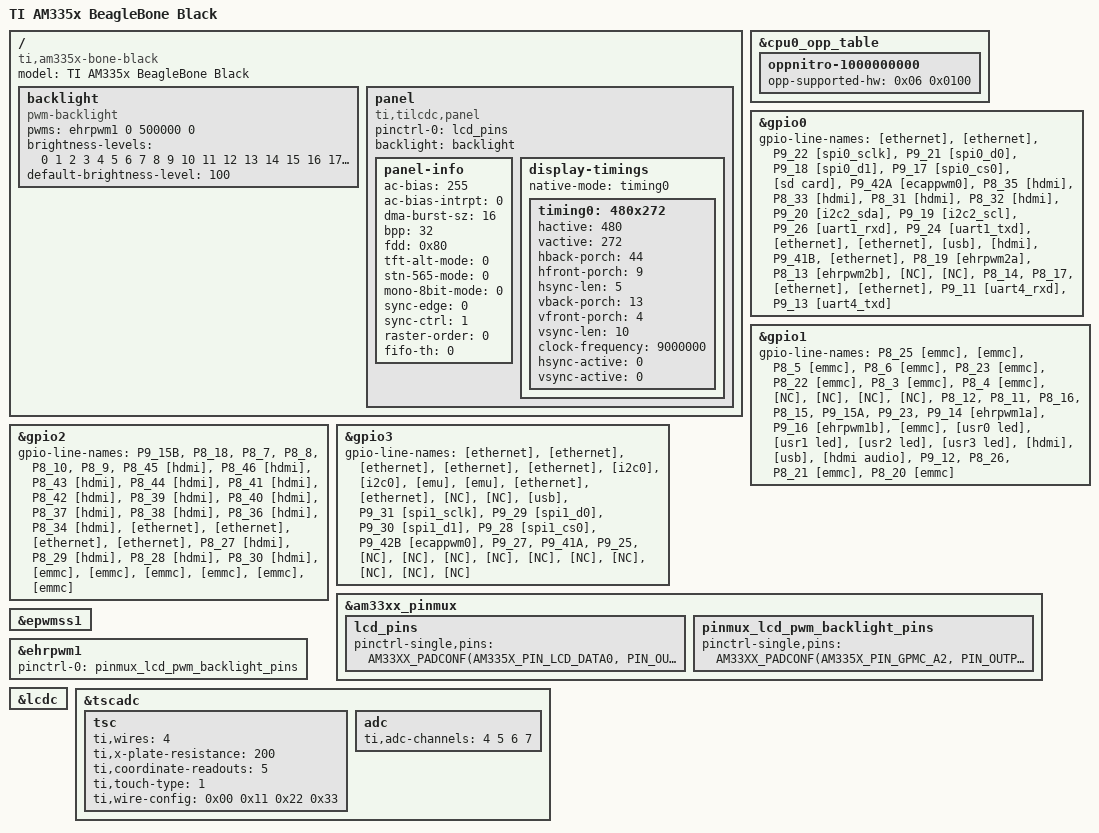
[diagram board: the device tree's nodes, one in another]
// SPDX-License-Identifier: GPL-2.0-only
/*
 * Copyright (C) 2012 Texas Instruments Incorporated - https://www.ti.com/
 */
/dts-v1/;

#include "am33xx.dtsi"
#include "am335x-bone-common.dtsi"
#include "am335x-boneblack-common.dtsi"

/ {
	model = "TI AM335x BeagleBone Black";
	compatible = "ti,am335x-bone-black", "ti,am335x-bone", "ti,am33xx";

	backlight: backlight {
		compatible  = "pwm-backlight";
		status = "okay";
		pwms = <&ehrpwm1 0 500000 0>;
		brightness-levels = < 0  1  2  3  4  5  6  7  8  9
				     10 11 12 13 14 15 16 17 18 19
				     20 21 22 23 24 25 26 27 28 29
				     30 31 32 33 34 35 36 37 38 39
				     40 41 42 43 44 45 46 47 48 49
				     50 51 52 53 54 55 56 57 58 59
				     60 61 62 63 64 65 66 67 68 69
				     70 71 72 73 74 75 76 77 78 79
				     80 81 82 83 84 85 86 87 88 89
				     90 91 92 93 94 95 96 97 98 99
				    100>;
		default-brightness-level = <100>;
	};

	panel {
		compatible = "ti,tilcdc,panel";
		status = "okay";
		pinctrl-names = "default";
		pinctrl-0 = <&lcd_pins>;
		backlight = <&backlight>;

		panel-info {
			ac-bias           = <255>;
			ac-bias-intrpt    = <0>;
			dma-burst-sz      = <16>;
			bpp               = <32>;
			fdd               = <0x80>;
			tft-alt-mode      = <0>;
			stn-565-mode      = <0>;
			mono-8bit-mode    = <0>;
			sync-edge         = <0>;
			sync-ctrl         = <1>;
			raster-order      = <0>;
			fifo-th           = <0>;
		};

		display-timings {
			native-mode = <&timing0>;
			timing0: 480x272 {
				hactive         = <480>;
				vactive         = <272>;
				hback-porch     = <44>;
				hfront-porch    = <9>;
				hsync-len       = <5>;
				vback-porch     = <13>;
				vfront-porch    = <4>;
				vsync-len       = <10>;
				clock-frequency = <9000000>;
				hsync-active    = <0>;
				vsync-active    = <0>;
			};
		};
	};
};

&cpu0_opp_table {
	/*
	 * All PG 2.0 silicon may not support 1GHz but some of the early
	 * BeagleBone Blacks have PG 2.0 silicon which is guaranteed
	 * to support 1GHz OPP so enable it for PG 2.0 on this board.
	 */
	oppnitro-1000000000 {
		opp-supported-hw = <0x06 0x0100>;
	};
};

&gpio0 {
	gpio-line-names =
		"[ethernet]",
		"[ethernet]",
		"P9_22 [spi0_sclk]",
		"P9_21 [spi0_d0]",
		"P9_18 [spi0_d1]",
		"P9_17 [spi0_cs0]",
		"[sd card]",
		"P9_42A [ecappwm0]",
		"P8_35 [hdmi]",
		"P8_33 [hdmi]",
		"P8_31 [hdmi]",
		"P8_32 [hdmi]",
		"P9_20 [i2c2_sda]",
		"P9_19 [i2c2_scl]",
		"P9_26 [uart1_rxd]",
		"P9_24 [uart1_txd]",
		"[ethernet]",
		"[ethernet]",
		"[usb]",
		"[hdmi]",
		"P9_41B",
		"[ethernet]",
		"P8_19 [ehrpwm2a]",
		"P8_13 [ehrpwm2b]",
		"[NC]",
		"[NC]",
		"P8_14",
		"P8_17",
		"[ethernet]",
		"[ethernet]",
		"P9_11 [uart4_rxd]",
		"P9_13 [uart4_txd]";
};

&gpio1 {
	gpio-line-names =
		"P8_25 [emmc]",
		"[emmc]",
		"P8_5 [emmc]",
		"P8_6 [emmc]",
		"P8_23 [emmc]",
		"P8_22 [emmc]",
		"P8_3 [emmc]",
		"P8_4 [emmc]",
		"[NC]",
		"[NC]",
		"[NC]",
		"[NC]",
		"P8_12",
		"P8_11",
		"P8_16",
		"P8_15",
		"P9_15A",
		"P9_23",
		"P9_14 [ehrpwm1a]",
		"P9_16 [ehrpwm1b]",
		"[emmc]",
		"[usr0 led]",
		"[usr1 led]",
		"[usr2 led]",
		"[usr3 led]",
		"[hdmi]",
		"[usb]",
		"[hdmi audio]",
		"P9_12",
		"P8_26",
		"P8_21 [emmc]",
		"P8_20 [emmc]";
};

&gpio2 {
	gpio-line-names =
		"P9_15B",
		"P8_18",
		"P8_7",
		"P8_8",
		"P8_10",
		"P8_9",
		"P8_45 [hdmi]",
		"P8_46 [hdmi]",
		"P8_43 [hdmi]",
		"P8_44 [hdmi]",
		"P8_41 [hdmi]",
		"P8_42 [hdmi]",
		"P8_39 [hdmi]",
		"P8_40 [hdmi]",
		"P8_37 [hdmi]",
		"P8_38 [hdmi]",
		"P8_36 [hdmi]",
		"P8_34 [hdmi]",
		"[ethernet]",
		"[ethernet]",
		"[ethernet]",
		"[ethernet]",
		"P8_27 [hdmi]",
		"P8_29 [hdmi]",
		"P8_28 [hdmi]",
		"P8_30 [hdmi]",
		"[emmc]",
		"[emmc]",
		"[emmc]",
		"[emmc]",
		"[emmc]",
		"[emmc]";
};

&gpio3 {
	gpio-line-names =
		"[ethernet]",
		"[ethernet]",
		"[ethernet]",
		"[ethernet]",
		"[ethernet]",
		"[i2c0]",
		"[i2c0]",
		"[emu]",
		"[emu]",
		"[ethernet]",
		"[ethernet]",
		"[NC]",
		"[NC]",
		"[usb]",
		"P9_31 [spi1_sclk]",
		"P9_29 [spi1_d0]",
		"P9_30 [spi1_d1]",
		"P9_28 [spi1_cs0]",
		"P9_42B [ecappwm0]",
		"P9_27",
		"P9_41A",
		"P9_25",
		"[NC]",
		"[NC]",
		"[NC]",
		"[NC]",
		"[NC]",
		"[NC]",
		"[NC]",
		"[NC]",
		"[NC]",
		"[NC]";
};

&am33xx_pinmux {

	lcd_pins: lcd_pins {
		pinctrl-single,pins = <
			AM33XX_PADCONF(AM335X_PIN_LCD_DATA0, PIN_OUTPUT, MUX_MODE0)
			AM33XX_PADCONF(AM335X_PIN_LCD_DATA1, PIN_OUTPUT, MUX_MODE0)
			AM33XX_PADCONF(AM335X_PIN_LCD_DATA2, PIN_OUTPUT, MUX_MODE0)
			AM33XX_PADCONF(AM335X_PIN_LCD_DATA3, PIN_OUTPUT, MUX_MODE0)
			AM33XX_PADCONF(AM335X_PIN_LCD_DATA4, PIN_OUTPUT, MUX_MODE0)
			AM33XX_PADCONF(AM335X_PIN_LCD_DATA5, PIN_OUTPUT, MUX_MODE0)
			AM33XX_PADCONF(AM335X_PIN_LCD_DATA6, PIN_OUTPUT, MUX_MODE0)
			AM33XX_PADCONF(AM335X_PIN_LCD_DATA7, PIN_OUTPUT, MUX_MODE0)
			AM33XX_PADCONF(AM335X_PIN_LCD_DATA8, PIN_OUTPUT, MUX_MODE0)
			AM33XX_PADCONF(AM335X_PIN_LCD_DATA9, PIN_OUTPUT, MUX_MODE0)
			AM33XX_PADCONF(AM335X_PIN_LCD_DATA10, PIN_OUTPUT, MUX_MODE0)
			AM33XX_PADCONF(AM335X_PIN_LCD_DATA11, PIN_OUTPUT, MUX_MODE0)
			AM33XX_PADCONF(AM335X_PIN_LCD_DATA12, PIN_OUTPUT, MUX_MODE0)
			AM33XX_PADCONF(AM335X_PIN_LCD_DATA13, PIN_OUTPUT, MUX_MODE0)
			AM33XX_PADCONF(AM335X_PIN_LCD_DATA14, PIN_OUTPUT, MUX_MODE0)
			AM33XX_PADCONF(AM335X_PIN_LCD_DATA15, PIN_OUTPUT, MUX_MODE0)
			AM33XX_PADCONF(AM335X_PIN_LCD_VSYNC, PIN_OUTPUT_PULLDOWN, MUX_MODE0)
			AM33XX_PADCONF(AM335X_PIN_LCD_HSYNC, PIN_OUTPUT_PULLDOWN, MUX_MODE0)
			AM33XX_PADCONF(AM335X_PIN_LCD_PCLK, PIN_OUTPUT_PULLDOWN, MUX_MODE0)
			AM33XX_PADCONF(AM335X_PIN_LCD_AC_BIAS_EN, PIN_OUTPUT_PULLDOWN, MUX_MODE0)
		>;
	};

	pinmux_lcd_pwm_backlight_pins: pinmux_lcd_pwm_backlight_pins {
		pinctrl-single,pins = <
			AM33XX_PADCONF(AM335X_PIN_GPMC_A2, PIN_OUTPUT, MUX_MODE6)
		>;
	};
};

&epwmss1 {
	status = "okay";
};

&ehrpwm1 {
	status = "okay";
	pinctrl-names = "default";
	pinctrl-0 = <&pinmux_lcd_pwm_backlight_pins>;
};

&lcdc {
	status = "okay";
};

&tscadc {
	status = "okay";

	tsc {
		ti,wires = <4>;
		ti,x-plate-resistance = <200>;
		ti,coordinate-readouts = <5>;
		ti,touch-type = <1>;
		ti,wire-config = <0x00 0x11 0x22 0x33>;
	};

	adc {
		ti,adc-channels = <4 5 6 7>;
	};
};
